AUTOSAR XML (schema 4-0-3)
package /ComponentTypes
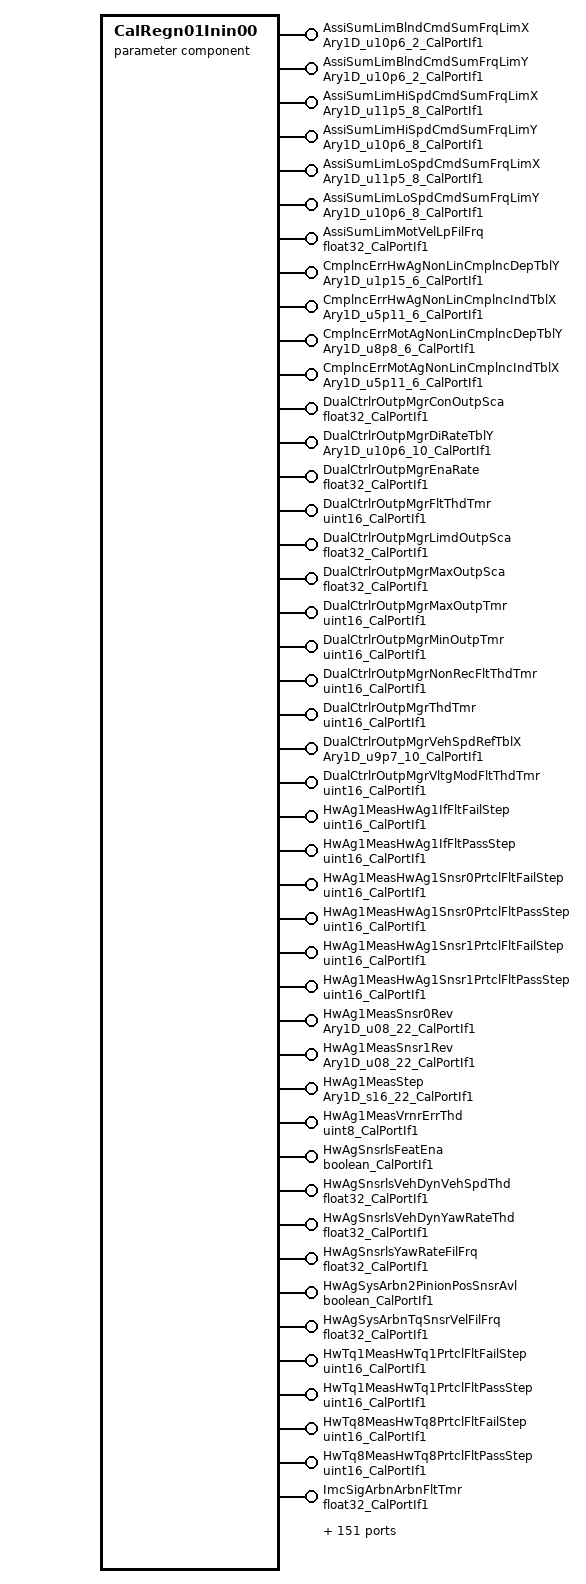
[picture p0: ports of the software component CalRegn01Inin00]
  parameter sw component type CalRegn01Inin00
    195 x provide port:
      AssiSumLimBlndCmdSumFrqLimX: parameter-provide-com-spec{init-value=[0, 32704], parameter=Ary1D}, provided-interface=Ary1D_u10p6_2_CalPortIf1
      AssiSumLimBlndCmdSumFrqLimY: parameter-provide-com-spec{init-value=[64, 0], parameter=Ary1D}, provided-interface=Ary1D_u10p6_2_CalPortIf1
      AssiSumLimHiSpdCmdSumFrqLimX: parameter-provide-com-spec{init-value=[0, 3200, 8000, 9600, 16000, 24000, 32000, 43200], parameter=Ary1D}, provided-interface=Ary1D_u11p5_8_CalPortIf1
      AssiSumLimHiSpdCmdSumFrqLimY: parameter-provide-com-spec{init-value=8 x 32000, parameter=Ary1D}, provided-interface=Ary1D_u10p6_8_CalPortIf1
      AssiSumLimLoSpdCmdSumFrqLimX: parameter-provide-com-spec{init-value=[0, 3200, 8000, 9600, 16000, 24000, 32000, 43200], parameter=Ary1D}, provided-interface=Ary1D_u11p5_8_CalPortIf1
      AssiSumLimLoSpdCmdSumFrqLimY: parameter-provide-com-spec{init-value=8 x 32000, parameter=Ary1D}, provided-interface=Ary1D_u10p6_8_CalPortIf1
      AssiSumLimMotVelLpFilFrq: parameter-provide-com-spec{init-value=100, parameter=Val}, provided-interface=float32_CalPortIf1
      CmplncErrHwAgNonLinCmplncDepTblY: parameter-provide-com-spec{init-value=6 x 0, parameter=Ary1D}, provided-interface=Ary1D_u1p15_6_CalPortIf1
      CmplncErrHwAgNonLinCmplncIndTblX: parameter-provide-com-spec{init-value=[0, 1024, 3072, 6144, 10240, 16384], parameter=Ary1D}, provided-interface=Ary1D_u5p11_6_CalPortIf1
      CmplncErrMotAgNonLinCmplncDepTblY: parameter-provide-com-spec{init-value=6 x 0, parameter=Ary1D}, provided-interface=Ary1D_u8p8_6_CalPortIf1
      CmplncErrMotAgNonLinCmplncIndTblX: parameter-provide-com-spec{init-value=[0, 1024, 3072, 6144, 10240, 16384], parameter=Ary1D}, provided-interface=Ary1D_u5p11_6_CalPortIf1
      DualCtrlrOutpMgrConOutpSca: parameter-provide-com-spec{init-value=0.5, parameter=Val}, provided-interface=float32_CalPortIf1
      DualCtrlrOutpMgrDiRateTblY: parameter-provide-com-spec{init-value=10 x 6400, parameter=Ary1D}, provided-interface=Ary1D_u10p6_10_CalPortIf1
      DualCtrlrOutpMgrEnaRate: parameter-provide-com-spec{init-value=100, parameter=Val}, provided-interface=float32_CalPortIf1
      DualCtrlrOutpMgrFltThdTmr: parameter-provide-com-spec{init-value=20, parameter=Val}, provided-interface=uint16_CalPortIf1
      DualCtrlrOutpMgrLimdOutpSca: parameter-provide-com-spec{init-value=0.3, parameter=Val}, provided-interface=float32_CalPortIf1
      DualCtrlrOutpMgrMaxOutpSca: parameter-provide-com-spec{init-value=1, parameter=Val}, provided-interface=float32_CalPortIf1
      DualCtrlrOutpMgrMaxOutpTmr: parameter-provide-com-spec{init-value=100, parameter=Val}, provided-interface=uint16_CalPortIf1
      DualCtrlrOutpMgrMinOutpTmr: parameter-provide-com-spec{init-value=100, parameter=Val}, provided-interface=uint16_CalPortIf1
      DualCtrlrOutpMgrNonRecFltThdTmr: parameter-provide-com-spec{init-value=30, parameter=Val}, provided-interface=uint16_CalPortIf1
      DualCtrlrOutpMgrThdTmr: parameter-provide-com-spec{init-value=20, parameter=Val}, provided-interface=uint16_CalPortIf1
      DualCtrlrOutpMgrVehSpdRefTblX: parameter-provide-com-spec{init-value=[0, 1920, 5120, 7680, 9600, 12800, 16000, 16640, 17920, 20480], parameter=Ary1D}, provided-interface=Ary1D_u9p7_10_CalPortIf1
      DualCtrlrOutpMgrVltgModFltThdTmr: parameter-provide-com-spec{init-value=20, parameter=Val}, provided-interface=uint16_CalPortIf1
      HwAg1MeasHwAg1IfFltFailStep: parameter-provide-com-spec{init-value=2521, parameter=Val}, provided-interface=uint16_CalPortIf1
      HwAg1MeasHwAg1IfFltPassStep: parameter-provide-com-spec{init-value=1000, parameter=Val}, provided-interface=uint16_CalPortIf1
      HwAg1MeasHwAg1Snsr0PrtclFltFailStep: parameter-provide-com-spec{init-value=2521, parameter=Val}, provided-interface=uint16_CalPortIf1
      HwAg1MeasHwAg1Snsr0PrtclFltPassStep: parameter-provide-com-spec{init-value=1000, parameter=Val}, provided-interface=uint16_CalPortIf1
      HwAg1MeasHwAg1Snsr1PrtclFltFailStep: parameter-provide-com-spec{init-value=2521, parameter=Val}, provided-interface=uint16_CalPortIf1
      HwAg1MeasHwAg1Snsr1PrtclFltPassStep: parameter-provide-com-spec{init-value=1000, parameter=Val}, provided-interface=uint16_CalPortIf1
      HwAg1MeasSnsr0Rev: parameter-provide-com-spec{init-value=[0, 1, 1, 2, 2, 3, 3, 4, 4, 5, 5, 6, 6, 7, 7, 8, 8, 9, 9, 10, 10, 0], parameter=Ary1D}, provided-interface=Ary1D_u08_22_CalPortIf1
      HwAg1MeasSnsr1Rev: parameter-provide-com-spec{init-value=[0, 0, 1, 1, 2, 2, 3, 3, 4, 4, 5, 5, 6, 6, 7, 7, 8, 8, 9, 9, 0, 9], parameter=Ary1D}, provided-interface=Ary1D_u08_22_CalPortIf1
      HwAg1MeasStep: parameter-provide-com-spec{init-value=[0, -360, 36, -324, 72, -288, 108, -252, 144, -216, 180, -180, 216, -144, 252, -108, 288, -72, 324, -36, 360, -396], parameter=Ary1D}, provided-interface=Ary1D_s16_22_CalPortIf1
      HwAg1MeasVrnrErrThd: parameter-provide-com-spec{init-value=8, parameter=Val}, provided-interface=uint8_CalPortIf1
      HwAgSnsrlsFeatEna: parameter-provide-com-spec{init-value=0, parameter=Logl}, provided-interface=boolean_CalPortIf1
      HwAgSnsrlsVehDynVehSpdThd: parameter-provide-com-spec{init-value=65, parameter=Val}, provided-interface=float32_CalPortIf1
      HwAgSnsrlsVehDynYawRateThd: parameter-provide-com-spec{init-value=1, parameter=Val}, provided-interface=float32_CalPortIf1
      HwAgSnsrlsYawRateFilFrq: parameter-provide-com-spec{init-value=3, parameter=Val}, provided-interface=float32_CalPortIf1
      HwAgSysArbn2PinionPosSnsrAvl: parameter-provide-com-spec{init-value=1, parameter=Logl}, provided-interface=boolean_CalPortIf1
      HwAgSysArbnTqSnsrVelFilFrq: parameter-provide-com-spec{init-value=20, parameter=Val}, provided-interface=float32_CalPortIf1
      HwTq1MeasHwTq1PrtclFltFailStep: parameter-provide-com-spec{init-value=2521, parameter=Val}, provided-interface=uint16_CalPortIf1
      HwTq1MeasHwTq1PrtclFltPassStep: parameter-provide-com-spec{init-value=1000, parameter=Val}, provided-interface=uint16_CalPortIf1
      HwTq8MeasHwTq8PrtclFltFailStep: parameter-provide-com-spec{init-value=2521, parameter=Val}, provided-interface=uint16_CalPortIf1
      HwTq8MeasHwTq8PrtclFltPassStep: parameter-provide-com-spec{init-value=1000, parameter=Val}, provided-interface=uint16_CalPortIf1
      ImcSigArbnArbnFltTmr: parameter-provide-com-spec{init-value=20, parameter=Val}, provided-interface=float32_CalPortIf1
      ImcSigArbnHwAgArbnEna: parameter-provide-com-spec{init-value=1, parameter=Logl}, provided-interface=boolean_CalPortIf1
      ImcSigArbnHwAgArbnLpFil: parameter-provide-com-spec{init-value=5, parameter=Val}, provided-interface=float32_CalPortIf1
      ImcSigArbnHwAgArbnOffsLim: parameter-provide-com-spec{init-value=100, parameter=Val}, provided-interface=float32_CalPortIf1
      ImcSigArbnHwAgTarArbnEna: parameter-provide-com-spec{init-value=1, parameter=Logl}, provided-interface=boolean_CalPortIf1
      ImcSigArbnHwAgTarArbnLpFil: parameter-provide-com-spec{init-value=5, parameter=Val}, provided-interface=float32_CalPortIf1
      ImcSigArbnHwAgTarArbnOffsLim: parameter-provide-com-spec{init-value=100, parameter=Val}, provided-interface=float32_CalPortIf1
      ImcSigArbnHwTqArbnEna: parameter-provide-com-spec{init-value=1, parameter=Logl}, provided-interface=boolean_CalPortIf1
      ImcSigArbnHwTqArbnLpFil: parameter-provide-com-spec{init-value=5, parameter=Val}, provided-interface=float32_CalPortIf1
      ImcSigArbnHwTqArbnOffsLim: parameter-provide-com-spec{init-value=20, parameter=Val}, provided-interface=float32_CalPortIf1
      ImcSigArbnMotVelArbnEna: parameter-provide-com-spec{init-value=1, parameter=Logl}, provided-interface=boolean_CalPortIf1
      ImcSigArbnMotVelArbnLpFil: parameter-provide-com-spec{init-value=5, parameter=Val}, provided-interface=float32_CalPortIf1
      ImcSigArbnMotVelArbnOffsLim: parameter-provide-com-spec{init-value=50, parameter=Val}, provided-interface=float32_CalPortIf1
      ImcSigArbnPosnServoArbnOffsLim: parameter-provide-com-spec{init-value=2, parameter=Val}, provided-interface=float32_CalPortIf1
      ImcSigArbnPosnServoIntgtrStArbnEna: parameter-provide-com-spec{init-value=1, parameter=Logl}, provided-interface=boolean_CalPortIf1
      ImcSigArbnPosnServoIntgtrStArbnLpFil: parameter-provide-com-spec{init-value=5, parameter=Val}, provided-interface=float32_CalPortIf1
      ImcSigArbnPosnTrakg1ArbnOffsLim: parameter-provide-com-spec{init-value=200, parameter=Val}, provided-interface=float32_CalPortIf1
      ImcSigArbnPosnTrakg2ArbnOffsLim: parameter-provide-com-spec{init-value=3000, parameter=Val}, provided-interface=float32_CalPortIf1
      ImcSigArbnPullCmpLongTermIntgtrStArbnEna: parameter-provide-com-spec{init-value=1, parameter=Logl}, provided-interface=boolean_CalPortIf1
      ImcSigArbnPullCmpLongTermIntgtrStArbnLpFil: parameter-provide-com-spec{init-value=5, parameter=Val}, provided-interface=float32_CalPortIf1
      ImcSigArbnPullCmpShoTermIntgtrStArbnEna: parameter-provide-com-spec{init-value=1, parameter=Logl}, provided-interface=boolean_CalPortIf1
      ImcSigArbnPullCmpShoTermIntgtrStArbnLpFil: parameter-provide-com-spec{init-value=5, parameter=Val}, provided-interface=float32_CalPortIf1
      ImcSigArbnSysStTmr: parameter-provide-com-spec{init-value=20, parameter=Val}, provided-interface=float32_CalPortIf1
      ImcSigArbnTrakgIntgtrSt1ArbnEna: parameter-provide-com-spec{init-value=1, parameter=Logl}, provided-interface=boolean_CalPortIf1
      ImcSigArbnTrakgIntgtrSt1ArbnLpFil: parameter-provide-com-spec{init-value=5, parameter=Val}, provided-interface=float32_CalPortIf1
      ImcSigArbnTrakgIntgtrSt2ArbnEna: parameter-provide-com-spec{init-value=1, parameter=Logl}, provided-interface=boolean_CalPortIf1
      ImcSigArbnTrakgIntgtrSt2ArbnLpFil: parameter-provide-com-spec{init-value=5, parameter=Val}, provided-interface=float32_CalPortIf1
      ImcSigArbnVehSpdArbnEna: parameter-provide-com-spec{init-value=1, parameter=Logl}, provided-interface=boolean_CalPortIf1
      ImcSigArbnVehSpdArbnLpFil: parameter-provide-com-spec{init-value=5, parameter=Val}, provided-interface=float32_CalPortIf1
      ImcSigArbnVehSpdArbnOffsLim: parameter-provide-com-spec{init-value=20, parameter=Val}, provided-interface=float32_CalPortIf1
      LimrCdngGainDecSlew: parameter-provide-com-spec{init-value=500, parameter=Val}, provided-interface=float32_CalPortIf1
      LimrCdngGainIncSlewX: parameter-provide-com-spec{init-value=[1280, 2560], parameter=Ary1D}, provided-interface=Ary1D_u9p7_2_CalPortIf1
      LimrCdngGainIncSlewY: parameter-provide-com-spec{init-value=[64000, 64000], parameter=Ary1D}, provided-interface=Ary1D_u9p7_2_CalPortIf1
      LimrCdngTqDecSlew: parameter-provide-com-spec{init-value=4400, parameter=Val}, provided-interface=float32_CalPortIf1
      LimrCdngTqIncSlewX: parameter-provide-com-spec{init-value=[1280, 2560], parameter=Ary1D}, provided-interface=Ary1D_u9p7_2_CalPortIf1
      LimrCdngTqIncSlewY: parameter-provide-com-spec{init-value=[35200, 35200], parameter=Ary1D}, provided-interface=Ary1D_u13p3_2_CalPortIf1
      McuDiagc2MilliSecCntrCompThd: parameter-provide-com-spec{init-value=5, parameter=Val}, provided-interface=uint16_CalPortIf1
      McuDiagcFltFailStep: parameter-provide-com-spec{init-value=16385, parameter=Val}, provided-interface=uint16_CalPortIf1
      McuDiagcFltPassStep: parameter-provide-com-spec{init-value=160, parameter=Val}, provided-interface=uint16_CalPortIf1
      MotTqCmdScaMax: parameter-provide-com-spec{init-value=1.1, parameter=Val}, provided-interface=float32_CalPortIf1
      MotTqCmdScaMin: parameter-provide-com-spec{init-value=0.9, parameter=Val}, provided-interface=float32_CalPortIf1
      MotTqTranlDampgCmdLim: parameter-provide-com-spec{init-value=3, parameter=Val}, provided-interface=float32_CalPortIf1
      MotTqTranlDampgDampgCoeff: parameter-provide-com-spec{init-value=0.036, parameter=Val}, provided-interface=float32_CalPortIf1
      MotTqTranlDampgRampEnd: parameter-provide-com-spec{init-value=0, parameter=Val}, provided-interface=u2p14_CalPortIf1
      MotTqTranlDampgTmrPt1: parameter-provide-com-spec{init-value=100, parameter=Val}, provided-interface=float32_CalPortIf1
      MotTqTranlDampgTmrPt2: parameter-provide-com-spec{init-value=1000, parameter=Val}, provided-interface=float32_CalPortIf1
      MotTqTranlDampgVehSpdBlndX: parameter-provide-com-spec{init-value=[0, 1280, 2560, 12800], parameter=Ary1D}, provided-interface=Ary1D_u9p7_4_CalPortIf1
      MotTqTranlDampgVelThd: parameter-provide-com-spec{init-value=2.3, parameter=Val}, provided-interface=float32_CalPortIf1
      PwrDiscnctBattVltgExtdNormThd: parameter-provide-com-spec{init-value=8, parameter=Val}, provided-interface=float32_CalPortIf1
      PwrDiscnctBattVltgNonExtdThd: parameter-provide-com-spec{init-value=7, parameter=Val}, provided-interface=float32_CalPortIf1
      PwrDiscnctChrgMinDeltaExtOper: parameter-provide-com-spec{init-value=5, parameter=Val}, provided-interface=float32_CalPortIf1
      PwrDiscnctChrgMinDeltaNonOper: parameter-provide-com-spec{init-value=0, parameter=Val}, provided-interface=float32_CalPortIf1
      PwrDiscnctChrgMinDeltaNormOper: parameter-provide-com-spec{init-value=6, parameter=Val}, provided-interface=float32_CalPortIf1
      PwrDiscnctChrgPmpDiagOpenThd: parameter-provide-com-spec{init-value=0.5, parameter=Val}, provided-interface=float32_CalPortIf1
      PwrDiscnctDeltaSwtClsThd: parameter-provide-com-spec{init-value=1, parameter=Val}, provided-interface=float32_CalPortIf1
      PwrDiscnctDeltaVltgClsThd: parameter-provide-com-spec{init-value=0.5, parameter=Val}, provided-interface=float32_CalPortIf1
      PwrDiscnctDeltaVltgOpenThd: parameter-provide-com-spec{init-value=2, parameter=Val}, provided-interface=float32_CalPortIf1
      PwrDiscnctFltFailStep: parameter-provide-com-spec{init-value=4, parameter=Val}, provided-interface=uint16_CalPortIf1
      PwrDiscnctFltPassStep: parameter-provide-com-spec{init-value=1, parameter=Val}, provided-interface=uint16_CalPortIf1
      PwrDiscnctFltThd: parameter-provide-com-spec{init-value=100, parameter=Val}, provided-interface=uint16_CalPortIf1
      PwrDiscnctMtrMtnThd: parameter-provide-com-spec{init-value=100, parameter=Val}, provided-interface=float32_CalPortIf1
      PwrDiscnctPwrDiscnctRtFltFailStep: parameter-provide-com-spec{init-value=1308, parameter=Val}, provided-interface=uint16_CalPortIf1
      PwrDiscnctPwrDiscnctRtFltPassStep: parameter-provide-com-spec{init-value=327, parameter=Val}, provided-interface=uint16_CalPortIf1
      PwrDiscnctSwtDiagOpenThd: parameter-provide-com-spec{init-value=0.5, parameter=Val}, provided-interface=float32_CalPortIf1
      SysFricLrngAvrgFricFrq: parameter-provide-com-spec{init-value=0.1, parameter=Val}, provided-interface=float32_CalPortIf1
      SysFricLrngBasLineEolFric: parameter-provide-com-spec{init-value=0, parameter=Val}, provided-interface=float32_CalPortIf1
      SysFricLrngBasLineFric: parameter-provide-com-spec{init-value=[0, 0, 0, 0], parameter=Ary1D}, provided-interface=Ary1D_f32_4_CalPortIf1
      SysFricLrngBasLineHys: parameter-provide-com-spec{init-value=8 x [0, 0, 0, 0], parameter=Ary2D}, provided-interface=Ary2D_f32_8_4_CalPortIf1
      SysFricLrngBasLineRngCntr: parameter-provide-com-spec{init-value=8 x [0, 0, 0], parameter=Ary2D}, provided-interface=Ary2D_u16_8_3_CalPortIf1
      SysFricLrngDataPrepLpFilFrq: parameter-provide-com-spec{init-value=30, parameter=Val}, provided-interface=float32_CalPortIf1
      SysFricLrngDebStep: parameter-provide-com-spec{init-value=656, parameter=Val}, provided-interface=uint16_CalPortIf1
      SysFricLrngEolFricDifHiLim: parameter-provide-com-spec{init-value=1, parameter=Val}, provided-interface=float32_CalPortIf1
      SysFricLrngEolFricDifLoLim: parameter-provide-com-spec{init-value=-1, parameter=Val}, provided-interface=float32_CalPortIf1
      SysFricLrngEolFricDifScagFac: parameter-provide-com-spec{init-value=0.8, parameter=Val}, provided-interface=float32_CalPortIf1
      SysFricLrngFricChgWght: parameter-provide-com-spec{init-value=[1, 1, 1, 1], parameter=Ary1D}, provided-interface=Ary1D_f32_4_CalPortIf1
      SysFricLrngFricDiagcThd: parameter-provide-com-spec{init-value=15, parameter=Val}, provided-interface=float32_CalPortIf1
      SysFricLrngFricHysHwAgPt: parameter-provide-com-spec{init-value=[-15, -5, 5, 15], parameter=Ary1D}, provided-interface=Ary1D_f32_4_CalPortIf1
      SysFricLrngFricOffs: parameter-provide-com-spec{init-value=0, parameter=Val}, provided-interface=float32_CalPortIf1
      SysFricLrngFricOffsHiLim: parameter-provide-com-spec{init-value=1, parameter=Val}, provided-interface=float32_CalPortIf1
      SysFricLrngFricOffsLoLim: parameter-provide-com-spec{init-value=-1, parameter=Val}, provided-interface=float32_CalPortIf1
      SysFricLrngFricOffsLpFilFrq: parameter-provide-com-spec{init-value=4, parameter=Val}, provided-interface=float32_CalPortIf1
      SysFricLrngGain: parameter-provide-com-spec{init-value=0.2, parameter=Val}, provided-interface=float32_CalPortIf1
      SysFricLrngHiFricDebStep: parameter-provide-com-spec{init-value=656, parameter=Val}, provided-interface=uint16_CalPortIf1
      SysFricLrngHiFricDiagcThd: parameter-provide-com-spec{init-value=30, parameter=Val}, provided-interface=float32_CalPortIf1
      SysFricLrngHwPosnAuthyThd: parameter-provide-com-spec{init-value=0.98, parameter=Val}, provided-interface=float32_CalPortIf1
      SysFricLrngHwVelConstrLim: parameter-provide-com-spec{init-value=360, parameter=Val}, provided-interface=float32_CalPortIf1
      SysFricLrngHwVelHiLim: parameter-provide-com-spec{init-value=180, parameter=Val}, provided-interface=float32_CalPortIf1
      SysFricLrngHwVelLoLim: parameter-provide-com-spec{init-value=10, parameter=Val}, provided-interface=float32_CalPortIf1
      SysFricLrngIgnCycFricChgLim: parameter-provide-com-spec{init-value=3, parameter=Val}, provided-interface=float32_CalPortIf1
      SysFricLrngIgnCycFricOffs: parameter-provide-com-spec{init-value=3, parameter=Val}, provided-interface=float32_CalPortIf1
      SysFricLrngIvsTrsmRatX: parameter-provide-com-spec{init-value=[0, 960, 1920, 2880, 3840, 5760, 8640, 11520, 14400, 17280], parameter=Ary1D}, provided-interface=Ary1D_u11p5_10_CalPortIf1
      SysFricLrngIvsTrsmRatY: parameter-provide-com-spec{init-value=10 x 24269, parameter=Ary1D}, provided-interface=Ary1D_u6p10_10_CalPortIf1
      SysFricLrngLatAHiLim: parameter-provide-com-spec{init-value=10, parameter=Val}, provided-interface=float32_CalPortIf1
      SysFricLrngLatALoLim: parameter-provide-com-spec{init-value=0, parameter=Val}, provided-interface=float32_CalPortIf1
      SysFricLrngMaskVehSpd: parameter-provide-com-spec{init-value=[1, 1, 1, 1], parameter=Ary1D}, provided-interface=Ary1D_logl_4_CalPortIf1
      SysFricLrngRngCntrThd: parameter-provide-com-spec{init-value=65534, parameter=Val}, provided-interface=uint16_CalPortIf1
      SysFricLrngThd: parameter-provide-com-spec{init-value=1, parameter=Val}, provided-interface=uint32_CalPortIf1
      SysFricLrngTHiLim: parameter-provide-com-spec{init-value=100, parameter=Val}, provided-interface=float32_CalPortIf1
      SysFricLrngTLoLim: parameter-provide-com-spec{init-value=0, parameter=Val}, provided-interface=float32_CalPortIf1
      SysFricLrngVehSpd: parameter-provide-com-spec{init-value=[[0, 5], [60, 80], [80, 100], [100, 120]], parameter=Ary2D}, provided-interface=Ary2D_f32_4_2_CalPortIf1
      SysGlbPrmMotPoleCnt: parameter-provide-com-spec{init-value=6, parameter=Val}, provided-interface=uint8_CalPortIf1
      SysGlbPrmSysTqRat: parameter-provide-com-spec{init-value=20, parameter=Val}, provided-interface=float32_CalPortIf1
      SysGlbPrmTorsBarStfn: parameter-provide-com-spec{init-value=2.5, parameter=Val}, provided-interface=float32_CalPortIf1
      SysGlbPrmVehSpdBilnrSeln: parameter-provide-com-spec{init-value=[0, 640, 1920, 3840, 7680, 10240, 12800, 15360, 19200, 23040, 25600, 28160], parameter=Ary1D}, provided-interface=Ary1D_u9p7_12_CalPortIf1
      TEstimnAmbPwrMplr: parameter-provide-com-spec{init-value=[0.01, 0.01, 0.01], parameter=Ary1D}, provided-interface=Ary1D_f32_3_CalPortIf1
      TEstimnAmbTSca: parameter-provide-com-spec{init-value=[0.9, 0.9, 0.9], parameter=Ary1D}, provided-interface=Ary1D_f32_3_CalPortIf1
      TEstimnAssiMechAmbLpFilFrq: parameter-provide-com-spec{init-value=0.024, parameter=Val}, provided-interface=float32_CalPortIf1
      TEstimnAssiMechAmbLpFilFrqDualEcuFltMtgtn: parameter-provide-com-spec{init-value=0.024, parameter=Val}, provided-interface=float32_CalPortIf1
      TEstimnAssiMechAmbLpFilFrqFetMtgtnEna: parameter-provide-com-spec{init-value=0.024, parameter=Val}, provided-interface=float32_CalPortIf1
      TEstimnAssiMechAmbMplr: parameter-provide-com-spec{init-value=[0.01, 0.01, 0.01], parameter=Ary1D}, provided-interface=Ary1D_f32_3_CalPortIf1
      TEstimnAssiMechCorrLim: parameter-provide-com-spec{init-value=[60, 60, 60], parameter=Ary1D}, provided-interface=Ary1D_f32_3_CalPortIf1
      TEstimnAssiMechDampgSca: parameter-provide-com-spec{init-value=[0.0001, 0.0001, 0.0001], parameter=Ary1D}, provided-interface=Ary1D_f32_3_CalPortIf1
      TEstimnAssiMechDftT: parameter-provide-com-spec{init-value=[50, 50, 50], parameter=Ary1D}, provided-interface=Ary1D_f32_3_CalPortIf1
      TEstimnAssiMechLLFilCoeffA1: parameter-provide-com-spec{init-value=[0.99996858, 0.99996858, 0.99996858], parameter=Ary1D}, provided-interface=Ary1D_f32_3_CalPortIf1
      TEstimnAssiMechLLFilCoeffB0: parameter-provide-com-spec{init-value=[0.4761987, 0.4761987, 0.4761987], parameter=Ary1D}, provided-interface=Ary1D_f32_3_CalPortIf1
      TEstimnAssiMechLLFilCoeffB1: parameter-provide-com-spec{init-value=[-0.4761673, -0.4761673, -0.4761673], parameter=Ary1D}, provided-interface=Ary1D_f32_3_CalPortIf1
      TEstimnAssiMechSlew: parameter-provide-com-spec{init-value=[1, 1, 1], parameter=Ary1D}, provided-interface=Ary1D_f32_3_CalPortIf1
      TEstimnCorrnTAssiMech: parameter-provide-com-spec{init-value=[0, 0, 0], parameter=Ary1D}, provided-interface=Ary1D_f32_3_CalPortIf1
      TEstimnCorrnTCu: parameter-provide-com-spec{init-value=[0, 0, 0], parameter=Ary1D}, provided-interface=Ary1D_f32_3_CalPortIf1
      TEstimnCorrnTMag: parameter-provide-com-spec{init-value=[0, 0, 0], parameter=Ary1D}, provided-interface=Ary1D_f32_3_CalPortIf1
      TEstimnCorrnTSi: parameter-provide-com-spec{init-value=[0, 0, 0], parameter=Ary1D}, provided-interface=Ary1D_f32_3_CalPortIf1
      TEstimnCuAmbLpFilFrq: parameter-provide-com-spec{init-value=0.024, parameter=Val}, provided-interface=float32_CalPortIf1
      TEstimnCuAmbLpFilFrqDualEcuFltMtgtn: parameter-provide-com-spec{init-value=0.024, parameter=Val}, provided-interface=float32_CalPortIf1
      TEstimnCuAmbLpFilFrqFetMtgtnEna: parameter-provide-com-spec{init-value=0.024, parameter=Val}, provided-interface=float32_CalPortIf1
      TEstimnCuAmbMplr: parameter-provide-com-spec{init-value=[0.75, 0.75, 0.75], parameter=Ary1D}, provided-interface=Ary1D_f32_3_CalPortIf1
      TEstimnCuCorrnLim: parameter-provide-com-spec{init-value=[80, 80, 80], parameter=Ary1D}, provided-interface=Ary1D_f32_3_CalPortIf1
      TEstimnCuLLFilCoeffA1: parameter-provide-com-spec{init-value=[0.999943, 0.999943, 0.999943], parameter=Ary1D}, provided-interface=Ary1D_f32_3_CalPortIf1
      TEstimnCuLLFilCoeffB0: parameter-provide-com-spec{init-value=[0.86667, 0.86667, 0.86667], parameter=Ary1D}, provided-interface=Ary1D_f32_3_CalPortIf1
      TEstimnCuLLFilCoeffB1: parameter-provide-com-spec{init-value=[-0.866613, -0.866613, -0.866613], parameter=Ary1D}, provided-interface=Ary1D_f32_3_CalPortIf1
      TEstimnEngTSca: parameter-provide-com-spec{init-value=[0.1, 0.1, 0.1], parameter=Ary1D}, provided-interface=Ary1D_f32_3_CalPortIf1
      TEstimnMagAmbLpFilFrq: parameter-provide-com-spec{init-value=0.024, parameter=Val}, provided-interface=float32_CalPortIf1
      TEstimnMagAmbLpFilFrqDualEcuFltMtgtn: parameter-provide-com-spec{init-value=0.024, parameter=Val}, provided-interface=float32_CalPortIf1
      TEstimnMagAmbLpFilFrqFetMtgtnEna: parameter-provide-com-spec{init-value=0.024, parameter=Val}, provided-interface=float32_CalPortIf1
      TEstimnMagCorrnLim: parameter-provide-com-spec{init-value=[60, 60, 60], parameter=Ary1D}, provided-interface=Ary1D_f32_3_CalPortIf1
      TEstimnMagLLFilCoeffA1: parameter-provide-com-spec{init-value=[0.999962, 0.999962, 0.999962], parameter=Ary1D}, provided-interface=Ary1D_f32_3_CalPortIf1
      TEstimnMagLLFilCoeffB0: parameter-provide-com-spec{init-value=[0.571437, 0.571437, 0.571437], parameter=Ary1D}, provided-interface=Ary1D_f32_3_CalPortIf1
      TEstimnMagLLFilCoeffB1: parameter-provide-com-spec{init-value=[-0.571399, -0.571399, -0.571399], parameter=Ary1D}, provided-interface=Ary1D_f32_3_CalPortIf1
      TEstimnSiAmbLpFilFrq: parameter-provide-com-spec{init-value=0.024, parameter=Val}, provided-interface=float32_CalPortIf1
      TEstimnSiAmbLpFilFrqDualEcuFltMtgtn: parameter-provide-com-spec{init-value=0.024, parameter=Val}, provided-interface=float32_CalPortIf1
      TEstimnSiAmbLpFilFrqFetMtgtnEna: parameter-provide-com-spec{init-value=0.024, parameter=Val}, provided-interface=float32_CalPortIf1
      TEstimnSiAmbMplr: parameter-provide-com-spec{init-value=[0, 0, 0], parameter=Ary1D}, provided-interface=Ary1D_f32_3_CalPortIf1
      TEstimnSiCorrnLim: parameter-provide-com-spec{init-value=[60, 60, 60], parameter=Ary1D}, provided-interface=Ary1D_f32_3_CalPortIf1
      TEstimnSiLLFilCoeffA1: parameter-provide-com-spec{init-value=[0.999889, 0.999889, 0.999889], parameter=Ary1D}, provided-interface=Ary1D_f32_3_CalPortIf1
      TEstimnSiLLFilCoeffB0: parameter-provide-com-spec{init-value=[1.68568, 1.68568, 1.68568], parameter=Ary1D}, provided-interface=Ary1D_f32_3_CalPortIf1
      TEstimnSiLLFilCoeffB1: parameter-provide-com-spec{init-value=[-1.68556, -1.68556, -1.68556], parameter=Ary1D}, provided-interface=Ary1D_f32_3_CalPortIf1
      TEstimnTauAssiMech: parameter-provide-com-spec{init-value=[4000, 4000, 4000], parameter=Ary1D}, provided-interface=Ary1D_f32_3_CalPortIf1
      TEstimnTauCu: parameter-provide-com-spec{init-value=[79, 79, 79], parameter=Ary1D}, provided-interface=Ary1D_f32_3_CalPortIf1
      TEstimnTauMag: parameter-provide-com-spec{init-value=[50, 50, 50], parameter=Ary1D}, provided-interface=Ary1D_f32_3_CalPortIf1
      TEstimnTauSi: parameter-provide-com-spec{init-value=[214, 214, 214], parameter=Ary1D}, provided-interface=Ary1D_f32_3_CalPortIf1
      TEstimnWghtAvrgTDi: parameter-provide-com-spec{init-value=[0, 0, 0], parameter=Ary1D}, provided-interface=Ary1D_logl_3_CalPortIf1
      VehSigCdngLatASlewRate: parameter-provide-com-spec{init-value=10, parameter=Val}, provided-interface=float32_CalPortIf1
      VehSigCdngLtgASlewRate: parameter-provide-com-spec{init-value=50, parameter=Val}, provided-interface=float32_CalPortIf1
